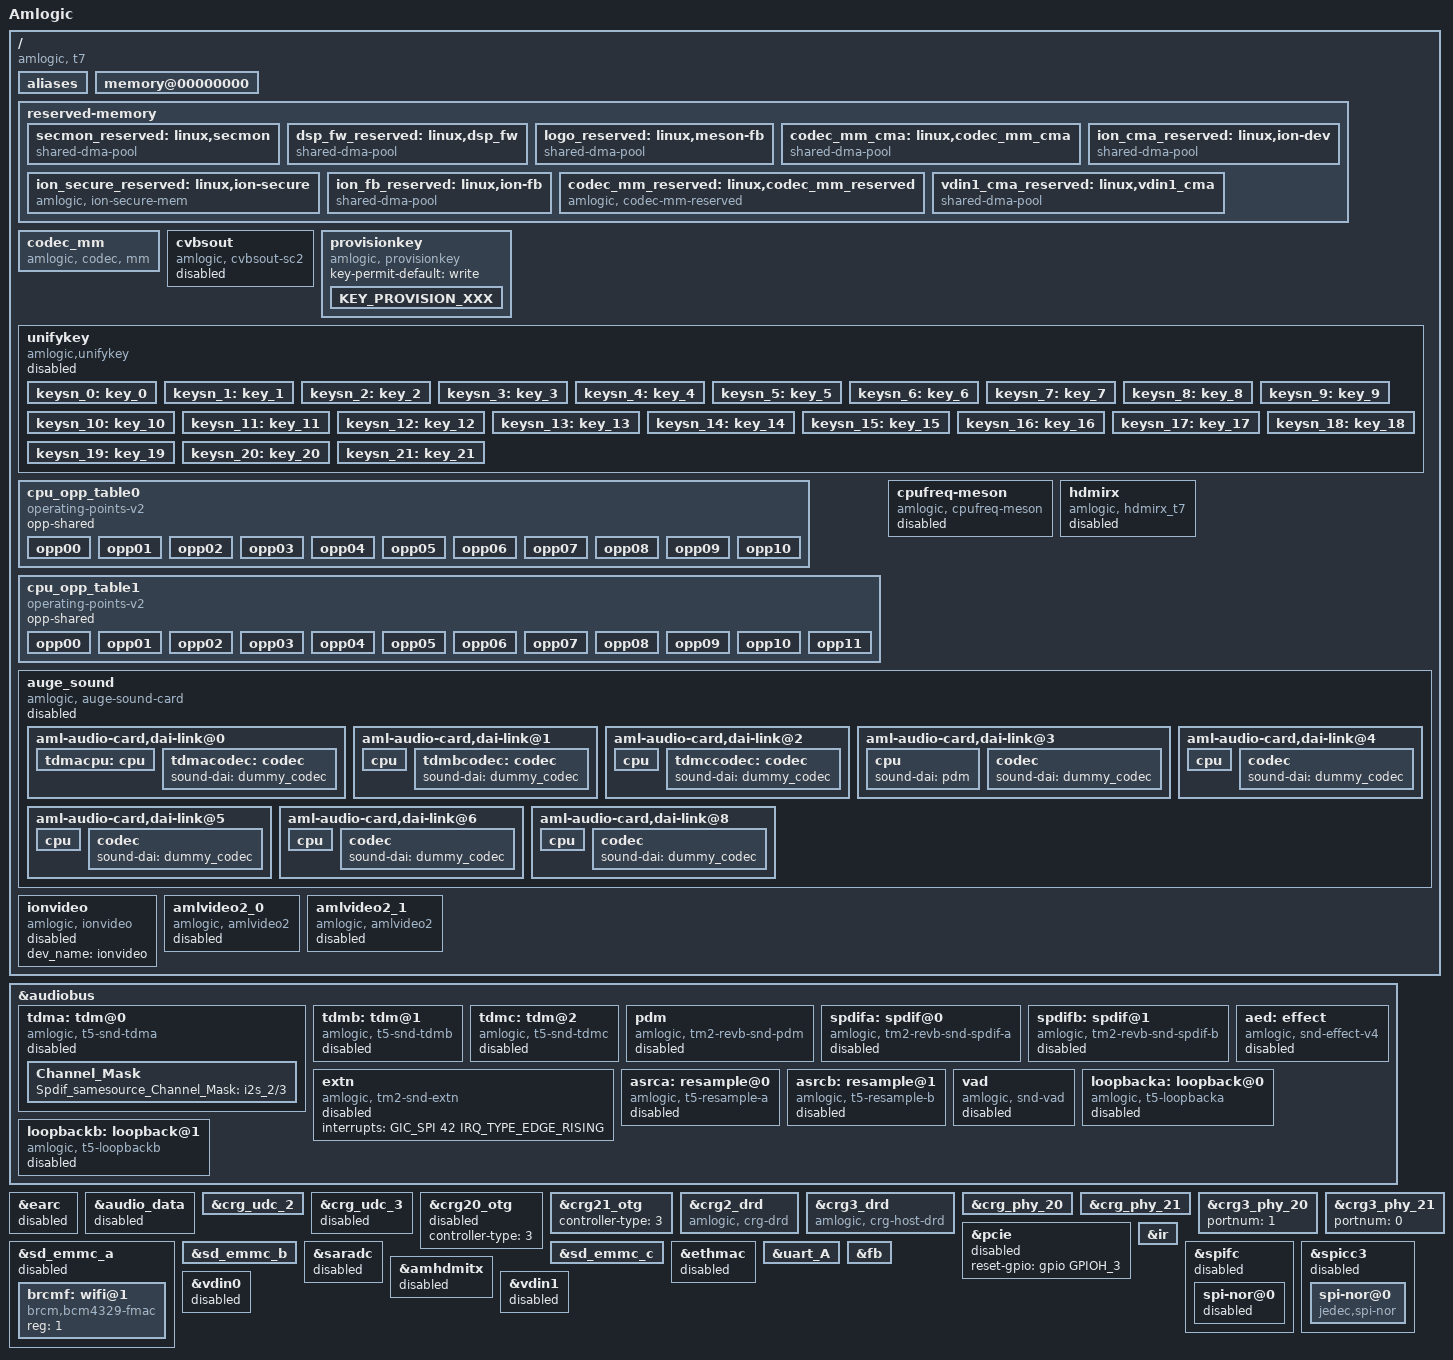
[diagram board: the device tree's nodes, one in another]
// SPDX-License-Identifier: (GPL-2.0+ OR MIT)
/*
 * Copyright (c) 2019 Amlogic, Inc. All rights reserved.
 */

/dts-v1/;

#include "mesont7.dtsi"
#include "partition_mbox_normal_P_32.dtsi"
#include <dt-bindings/input/input.h>
#include "mesont7_pxp-panel.dtsi"

/ {
	model = "Amlogic";
	amlogic-dt-id = "t7_pxp";
	compatible = "amlogic, t7";
	interrupt-parent = <&gic>;
	#address-cells = <2>;
	#size-cells = <2>;

	aliases {
		serial0 = &uart_A;
		serial1 = &uart_E;
		serial2 = &uart_C;
		serial3 = &uart_D;
		//serial4 = &uart_A;
		i2c0 = &i2c0;
		i2c1 = &i2c1;
		i2c2 = &i2c2;
		i2c3 = &i2c3;
		i2c4 = &i2c4;
		i2c5 = &i2c5;
		i2c6 = &i2c_AO_A;
		i2c7 = &i2c_AO_B;
		spi0 = &spifc;
		spi1 = &spicc0;
		spi2 = &spicc1;
		spi3 = &spicc2;
		spi4 = &spicc3;
		spi5 = &spicc4;
		spi6 = &spicc5;
		tsensor0 = &a73_tsensor;
		tsensor1 = &a53_tsensor;
		tsensor2 = &gpu_tsensor;
		tsensor3 = &nna_tsensor;
		tsensor4 = &hevc_tsensor;
		tsensor5 = &vpu_tsensor;
	};

	memory@00000000 {
		device_type = "memory";
		linux,usable-memory = <0x0 0x000000 0x0 0x40000000>;
	};

	reserved-memory {
		#address-cells = <2>;
		#size-cells = <2>;
		ranges;

		secmon_reserved:linux,secmon {
			compatible = "shared-dma-pool";
			reusable;
			size = <0x0 0x3400000>;
			alignment = <0x0 0x400000>;
			alloc-ranges = <0x0 0x05000000 0x0 0x3400000>;
			clear-map;
		};

		dsp_fw_reserved:linux,dsp_fw {
			compatible = "shared-dma-pool";
			reusable;
			size = <0x0 0x1000000>;
			alignment = <0x0 0x400000>;
			alloc-ranges = <0x0 0x40000000 0x0 0x1000000>;
		};

		/*dsp_shm_reserved:linux,dsp_shm {      */
		/*	compatible = "dspshmem";            */
		/*	reg = <0x0 0x40820000 0x0 0x80000>; */
		/*	size = <0x80000>;                   */
		/*};*/

		logo_reserved:linux,meson-fb {
			compatible = "shared-dma-pool";
			reusable;
			size = <0x0 0x800000>;
			alignment = <0x0 0x400000>;
			alloc-ranges = <0x0 0x3f800000 0x0 0x800000>;
		};

		codec_mm_cma:linux,codec_mm_cma {
			compatible = "shared-dma-pool";
			reusable;
			/* ion_codec_mm max can alloc size 80M*/
			size = <0x0 0xd000000>;
			alignment = <0x0 0x400000>;
			linux,contiguous-region;
			clear-map;
		};

		ion_cma_reserved:linux,ion-dev {
			compatible = "shared-dma-pool";
			reusable;
			size = <0x0 0x9800000>;
			alignment = <0x0 0x400000>;
		};
		/* secure ion for gpu,advice size is 0x8000000 */
		ion_secure_reserved:linux,ion-secure {
			compatible = "amlogic, ion-secure-mem";
			no-map;
			size = <0x0 0x0>;
			alignment = <0x0 0x400000>;
		};
		ion_fb_reserved:linux,ion-fb {
			compatible = "shared-dma-pool";
			reusable;
			/* 1920x1080x4x3 round up 4M align */
			size = <0x0 0x1c00000>;
			alignment = <0x0 0x400000>;
		};
		/* codec shared reserved */
		codec_mm_reserved:linux,codec_mm_reserved {
			compatible = "amlogic, codec-mm-reserved";
			size = <0x0 0x0>;
			alignment = <0x0 0x100000>;
			//no-map;
		};

		/*  vdin0 CMA pool */
		/*vdin0_cma_reserved:linux,vdin0_cma {*/
		/*	compatible = "shared-dma-pool";*/
		/*	reusable;*/
			/* up to 1920x1080 yuv422 8bit and 5 buffers
			 * 1920x1080x2x5 = 20 M
			 */
		/*	size = <0x0 0x01400000>;*/
		/*	alignment = <0x0 0x400000>;*/
		/*};*/
		/*  vdin1 CMA pool */
		vdin1_cma_reserved:linux,vdin1_cma {
			compatible = "shared-dma-pool";
			reusable;
			/* up to 1920x1080 yuv422 8bit and 5 buffers
			 * 1920x1080x2x5 = 20 M
			 */
			size = <0x0 0x01400000>;
			alignment = <0x0 0x400000>;
		};
	};
	codec_mm {
		compatible = "amlogic, codec, mm";
		memory-region = <&codec_mm_cma &codec_mm_reserved>;
		dev_name = "codec_mm";
		status = "okay";
	};

	cvbsout {
		compatible = "amlogic, cvbsout-sc2";
		status = "disabled";

		/* clk path */
		/* 0:vid_pll vid2_clk */
		/* 1:gp0_pll vid2_clk */
		/* 2:vid_pll vid1_clk */
		/* 3:gp0_pll vid1_clk */
		clk_path = <0>;

		/* performance: reg_address, reg_value */
		/* tm2 */
		performance = <0x1bf0  0x9
			0x1b56  0x333
			0x1b12  0x8080
			0x1b05  0xfd
			0x1c59  0xf850
			0xffff  0x0>; /* ending flag */
		performance_sarft = <0x1bf0  0x9
			0x1b56  0x333
			0x1b12  0x0
			0x1b05  0x9
			0x1c59  0xfc48
			0xffff  0x0>; /* ending flag */
		performance_revB_telecom = <0x1bf0  0x9
			0x1b56  0x546
			0x1b12  0x8080
			0x1b05  0x9
			0x1c59  0xf850
			0xffff  0x0>; /* ending flag */
	};

	provisionkey {
		compatible = "amlogic, provisionkey";
		status = "okay";
		key-permit-default = "write";
		//new key not need add dts if started with KEY_PROVISION_
		KEY_PROVISION_XXX { };
		//test_my_added_keyname { };
	};//End provisionkey

	unifykey{
		compatible = "amlogic,unifykey";
		status = "disabled";
		unifykey-num = <19>;
		unifykey-index-0 = <&keysn_0>;
		unifykey-index-1 = <&keysn_1>;
		unifykey-index-2 = <&keysn_2>;
		unifykey-index-3 = <&keysn_3>;
		unifykey-index-4 = <&keysn_4>;
		unifykey-index-5 = <&keysn_5>;
		unifykey-index-6 = <&keysn_6>;
		unifykey-index-7 = <&keysn_7>;
		unifykey-index-8 = <&keysn_8>;
		unifykey-index-9 = <&keysn_9>;
		unifykey-index-10= <&keysn_10>;
		unifykey-index-11= <&keysn_11>;
		unifykey-index-12= <&keysn_12>;
		unifykey-index-13= <&keysn_13>;
		unifykey-index-14= <&keysn_14>;
		unifykey-index-15= <&keysn_15>;
		unifykey-index-16= <&keysn_16>;
		unifykey-index-17= <&keysn_17>;
		unifykey-index-18= <&keysn_18>;
		unifykey-index-19= <&keysn_19>;
		unifykey-index-20= <&keysn_20>;
		unifykey-index-21= <&keysn_21>;

		keysn_0: key_0{
			key-name = "usid";
			key-device = "normal";
			key-permit = "read","write","del";
		};
		keysn_1:key_1{
			key-name = "mac";
			key-device = "normal";
			key-permit = "read","write","del";
		};
		keysn_2:key_2{
			key-name = "hdcp";
			key-device = "secure";
			key-type = "sha1";
			key-permit = "read","write","del";
		};
		keysn_3:key_3{
			key-name = "secure_boot_set";
			key-device = "efuse";
			key-permit = "write";
		};
		keysn_4:key_4{
			key-name = "mac_bt";
			key-device = "normal";
			key-permit = "read","write","del";
			key-type  = "mac";
		};
		keysn_5:key_5{
			key-name = "mac_wifi";
			key-device = "normal";
			key-permit = "read","write","del";
			key-type = "mac";
		};
		keysn_6:key_6{
			key-name = "hdcp2_tx";
			key-device = "normal";
			key-permit = "read","write","del";
		};
		keysn_7:key_7{
			key-name = "hdcp2_rx";
			key-device = "normal";
			key-permit = "read","write","del";
		};
		keysn_8:key_8{
			key-name = "widevinekeybox";
			key-device = "secure";
			key-permit = "read","write","del";
		};
		keysn_9:key_9{
			key-name = "deviceid";
			key-device = "normal";
			key-permit = "read","write","del";
		};
		keysn_10:key_10{
			key-name = "hdcp22_fw_private";
			key-device = "secure";
			key-permit = "read","write","del";
		};
		keysn_11:key_11{
			key-name = "PlayReadykeybox25";
			key-device = "secure";
			key-permit = "read","write","del";
		};
		keysn_12:key_12{
			key-name = "prpubkeybox";// PlayReady
			key-device = "secure";
			key-permit = "read","write","del";
		};
		keysn_13:key_13{
			key-name = "prprivkeybox";// PlayReady
			key-device = "secure";
			key-permit = "read","write","del";
		};
		keysn_14:key_14{
			key-name = "attestationkeybox";// attestation key
			key-device = "secure";
			key-permit = "read","write","del";
		};
		keysn_15:key_15{
			key-name = "region_code";
			key-device = "normal";
			key-permit = "read","write","del";
		};
		keysn_16:key_16{
			key-name = "netflix_mgkid";
			key-device = "secure";
			key-permit = "read","write","del";
		};
		keysn_17:key_17{
			key-name = "attestationdevidbox";// attest dev id box
			key-device = "secure";
			key-permit = "read","write","del";
		};
		keysn_18:key_18{
			key-name = "oemkey";
			key-device = "normal";
			key-permit = "read","write","del";
		};
		keysn_19:key_19{
			key-name = "lcd";
			key-device = "normal";
			key-permit = "read","write","del";
		};
		keysn_20:key_20{
			key-name = "lcd_extern";
			key-device = "normal";
			key-permit = "read","write","del";
		};
		keysn_21:key_21{
			key-name = "backlight";
			key-device = "normal";
			key-permit = "read","write","del";
		};
	};//End unifykey

	cpu_opp_table0: cpu_opp_table0 {
		compatible = "operating-points-v2";
		opp-shared;

		opp00 {
			opp-hz = /bits/ 64 <500000000>;
			opp-microvolt = <740000>;
		};
		opp01 {
			opp-hz = /bits/ 64 <666000000>;
			opp-microvolt = <740000>;
		};
		opp02 {
			opp-hz = /bits/ 64 <1000000000>;
			opp-microvolt = <770000>;
		};
		opp03 {
			opp-hz = /bits/ 64 <1200000000>;
			opp-microvolt = <790000>;
		};
		opp04 {
			opp-hz = /bits/ 64 <1392000000>;
			opp-microvolt = <820000>;
		};
		opp05 {
			opp-hz = /bits/ 64 <1512000000>;
			opp-microvolt = <870000>;
		};
		opp06 {
			opp-hz = /bits/ 64 <1608000000>;
			opp-microvolt = <910000>;
		};
		opp07 {
			opp-hz = /bits/ 64 <1704000000>;
			opp-microvolt = <960000>;
		};
		opp08 {
			opp-hz = /bits/ 64 <1800000000>;
			opp-microvolt = <980000>;
		};
		opp09 {
			opp-hz = /bits/ 64 <1896000000>;
			opp-microvolt = <1000000>;
		};
		opp10 {
			opp-hz = /bits/ 64 <2016000000>;
			opp-microvolt = <1030000>;
		};
	};

	cpu_opp_table1: cpu_opp_table1 {
		compatible = "operating-points-v2";
		opp-shared;

		opp00 {
			opp-hz = /bits/ 64 <500000000>;
			opp-microvolt = <739000>;
		};
		opp01 {
			opp-hz = /bits/ 64 <666000000>;
			opp-microvolt = <739000>;
		};
		opp02 {
			opp-hz = /bits/ 64 <1000000000>;
			opp-microvolt = <769000>;
		};
		opp03 {
			opp-hz = /bits/ 64 <1200000000>;
			opp-microvolt = <799000>;
		};
		opp04 {
			opp-hz = /bits/ 64 <1392000000>;
			opp-microvolt = <829000>;
		};
		opp05 {
			opp-hz = /bits/ 64 <1512000000>;
			opp-microvolt = <869000>;
		};
		opp06 {
			opp-hz = /bits/ 64 <1608000000>;
			opp-microvolt = <899000>;
		};
		opp07 {
			opp-hz = /bits/ 64 <1704000000>;
			opp-microvolt = <919000>;
		};
		opp08 {
			opp-hz = /bits/ 64 <1800000000>;
			opp-microvolt = <939000>;
		};
		opp09 {
			opp-hz = /bits/ 64 <1896000000>;
			opp-microvolt = <969000>;
		};
		opp10 {
			opp-hz = /bits/ 64 <2016000000>;
			opp-microvolt = <999000>;
		};
		opp11 {
			opp-hz = /bits/ 64 <2208000000>;
			opp-microvolt = <1029000>;
		};
	};

	cpufreq-meson {
		compatible = "amlogic, cpufreq-meson";
		status = "disabled";
	};

	hdmirx {
		compatible = "amlogic, hdmirx_t7";
		#address-cells=<1>;
		#size-cells=<1>;
		/*memory-region = <&hdmirx_emp_cma_reserved>;*/
		status = "disabled";
		pinctrl-names = "hdmirx_pins";
		pinctrl-0 = <&hdmirx_a_mux &hdmirx_b_mux
			&hdmirx_c_mux>;
		repeat = <0>;
		interrupts = <0 57 IRQ_TYPE_LEVEL_HIGH>;
		clocks =<&clkc CLKID_HDMIRX_CFG>,
			   <&clkc CLKID_HDMIRX_ACR>,
			   <&clkc CLKID_HDMIRX_METER>,
			   <&clkc CLKID_HDMIRX_2M>,
			   <&clkc CLKID_HDMIRX_5M>,
			   <&clkc CLKID_HDMIRX_HDCP>,
			   <&xtal>,
			   <&clkc CLKID_FCLK_DIV4>,
			   <&clkc CLKID_FCLK_DIV5>;
		clock-names = "cts_hdmirx_cfg_clk",
				"cts_hdmirx_acr_ref_clk",
				"cts_hdmirx_meter_clk",
				"cts_hdmirx_2m_clk",
				"cts_hdmirx_5m_clk",
				"cts_hdmirx_hdcp2x_eclk",
				"xtal",
				"fclk_div4",
				"fclk_div5";
		hdmirx_id = <0>;
		en_4k_2_2k = <0>;
		hpd_low_cec_off = <1>;
		arc_port = <1>;
		/* bit4: enable feature, bit3~0: port number */
		disable_port = <0x0>;
		/* MAP_ADDR_MODULE_CBUS */
		/* MAP_ADDR_MODULE_HIU */
		/* MAP_ADDR_MODULE_HDMIRX_CAPB3 */
		/* MAP_ADDR_MODULE_SEC_AHB */
		/* MAP_ADDR_MODULE_SEC_AHB2 */
		/* MAP_ADDR_MODULE_APB4 */
		/* MAP_ADDR_MODULE_TOP */
		/* MAP_ADDR_MODULE_CLK_CTRL */
		reg = < 0x0 0x0 0x0 0x0
			0x0 0xff63C000 0x0 0x2000
			0x0 0xffe0d000 0x0 0x2000
			0x0 0x0 0x0 0x0
			0x0 0x0 0x0 0x0
			0x0 0x0 0x0 0x0
			0x0 0xfe398000 0x0 0x7fff
			0x0 0xfe000000 0x0 0x1fff>;
	};

	/* Audio Related start */
	auge_sound {
		compatible = "amlogic, auge-sound-card";
		aml-audio-card,name = "AML-AUGESOUND";

		/*avout mute gpio*/
		//avout_mute-gpios = <&gpio GPIOH_5 GPIO_ACTIVE_HIGH>;
		//spk_mute-gpios = <&gpio GPIOD_2 GPIO_ACTIVE_LOW>;

		interrupts = <GIC_SPI 51 IRQ_TYPE_EDGE_RISING>;
		interrupt-names = "audio_exception64";

		status = "disabled";

		aml-audio-card,dai-link@0 {
			format = "i2s";
			mclk-fs = <256>;
			continuous-clock;
			//bitclock-inversion;
			//frame-inversion;
			/* master mode */
			bitclock-master = <&tdma>;
			frame-master = <&tdma>;
			/* slave mode */
			/*
			 * bitclock-master = <&tdmacodec>;
			 * frame-master = <&tdmacodec>;
			 */
			/* suffix-name, sync with android audio hal used for */
			suffix-name = "alsaPORT-i2s";
			tdmacpu: cpu {
				sound-dai = <&tdma>;
				dai-tdm-slot-tx-mask =
							<1 1>;
				dai-tdm-slot-rx-mask =
							<1 1>;
				dai-tdm-slot-num = <2>;
				dai-tdm-slot-width = <32>;
				system-clock-frequency = <12288000>;
			};
			tdmacodec: codec {
				sound-dai = <&dummy_codec>;
				//prefix-names = "AMP", "AMP1";
				//sound-dai = <&ad82584f &ad82584f1 &tl1_codec>;
			};
		};

		aml-audio-card,dai-link@1 {
			format = "i2s";
			mclk-fs = <256>;
			//continuous-clock;
			//bitclock-inversion;
			//frame-inversion;
			/* master mode */
			bitclock-master = <&tdmb>;
			frame-master = <&tdmb>;
			/* slave mode */
			//bitclock-master = <&tdmbcodec>;
			//frame-master = <&tdmbcodec>;
			/* suffix-name, sync with android audio hal used for */
			suffix-name = "alsaPORT-pcm";
			cpu {
				sound-dai = <&tdmb>;
				dai-tdm-slot-tx-mask = <1 1>;
				dai-tdm-slot-rx-mask = <1 1>;
				dai-tdm-slot-num = <2>;
				/*
				 * dai-tdm-slot-tx-mask =
				 *	<1 1 1 1 1 1 1 1>;
				 * dai-tdm-slot-rx-mask =
				 *	<1 1 1 1 1 1 1 1>;
				 * dai-tdm-slot-num = <8>;
				 */
				dai-tdm-slot-width = <32>;
				system-clock-frequency = <12288000>;
			};
			tdmbcodec: codec {
				sound-dai = <&dummy_codec>;
			};
		};

		aml-audio-card,dai-link@2 {
			format = "i2s";
			mclk-fs = <256>;
			//continuous-clock;
			//bitclock-inversion;
			//frame-inversion;
			/* master mode */
			bitclock-master = <&tdmc>;
			frame-master = <&tdmc>;
			/* slave mode */
			//bitclock-master = <&tdmccodec>;
			//frame-master = <&tdmccodec>;
			/* suffix-name, sync with android audio hal used for */
			//suffix-name = "alsaPORT-tdm";
			cpu {
				sound-dai = <&tdmc>;
				dai-tdm-slot-tx-mask = <1 1>;
				dai-tdm-slot-rx-mask = <1 1>;
				dai-tdm-slot-num = <2>;
				dai-tdm-slot-width = <32>;
				system-clock-frequency = <12288000>;
			};
			tdmccodec: codec {
				sound-dai = <&dummy_codec>;
			};
		};

		aml-audio-card,dai-link@3 {
			mclk-fs = <64>;
			/* suffix-name, sync with android audio hal used for */
			suffix-name = "alsaPORT-pdm";
			cpu {
				sound-dai = <&pdm>;
			};
			codec {
				sound-dai = <&dummy_codec>;
			};
		};

		aml-audio-card,dai-link@4 {
			mclk-fs = <128>;
			continuous-clock;
			/* suffix-name, sync with android audio hal used for */
			suffix-name = "alsaPORT-spdif";
			cpu {
				sound-dai = <&spdifa>;
				system-clock-frequency = <6144000>;
			};
			codec {
				sound-dai = <&dummy_codec>;
			};
		};

		aml-audio-card,dai-link@5 {
			mclk-fs = <128>;
			suffix-name = "alsaPORT-spdifb";
			cpu {
				sound-dai = <&spdifb>;
				system-clock-frequency = <6144000>;
			};
			codec {
				sound-dai = <&dummy_codec>;
			};
		};

		aml-audio-card,dai-link@6 {
			mclk-fs = <256>;
			suffix-name = "alsaPORT-tv";
			cpu {
				sound-dai = <&extn>;
				system-clock-frequency = <12288000>;
			};
			codec {
				sound-dai = <&dummy_codec>;
			};
		};
#if 0
		aml-audio-card,dai-link@7 {
			mclk-fs = <256>;
			suffix-name = "alsaPORT-earc";
			cpu {
				sound-dai = <&earc>;
				system-clock-frequency = <12288000>;
			};
			codec {
				sound-dai = <&dummy_codec>;
			};
		};
#endif
		aml-audio-card,dai-link@8 {
			mclk-fs = <256>;
			continuous-clock;
			suffix-name = "alsaPORT-loopback";
			cpu {
				sound-dai = <&loopbacka>;
				system-clock-frequency = <12288000>;
			};
			codec {
				sound-dai = <&dummy_codec>;
			};
		};
	};
	/* Audio Related end */

	ionvideo {
		compatible = "amlogic, ionvideo";
		dev_name = "ionvideo";
		status = "disabled";
	};

	amlvideo2_0 {
		compatible = "amlogic, amlvideo2";
		dev_name = "amlvideo2";
		status = "disabled";
		amlvideo2_id = <0>;
		cma_mode = <1>;
	};

	amlvideo2_1 {
		compatible = "amlogic, amlvideo2";
		dev_name = "amlvideo2";
		status = "disabled";
		amlvideo2_id = <1>;
		cma_mode = <1>;
	};
};

&audiobus {
	tdma:tdm@0 {
		compatible = "amlogic, t5-snd-tdma";
		#sound-dai-cells = <0>;

		dai-tdm-lane-slot-mask-in = <1 0>;
		dai-tdm-lane-slot-mask-out = <1 1 1 1>;
		dai-tdm-clk-sel = <0>;

		clocks = <&clkaudio CLKID_AUDIO_MCLK_A
				&clkaudio CLKID_AUDIO_MCLK_PAD0
				&clkc CLKID_MPLL0
				&clkc CLKID_MPLL1
				&clkaudio CLKID_AUDIO_SPDIFOUT_A>;
		clock-names = "mclk", "mclk_pad", "clk_srcpll",
			"samesource_srcpll", "samesource_clk";

		//pinctrl-names = "tdm_pins";
		//pinctrl-0 = <&tdm_a>;

		/*
		 * 0: tdmout_a;
		 * 1: tdmout_b;
		 * 2: tdmout_c;
		 * 3: spdifout;
		 * 4: spdifout_b;
		 */
		samesource_sel = <3>;

		/* In for ACODEC_ADC */
		tdmin-src-name = "acodec_adc";
		/*enable default mclk(12.288M), before extern codec start*/
		start_clk_enable = <1>;

		/*tdm clk tuning enable*/
		clk_tuning_enable = <1>;
		status = "disabled";

		/* !!!For --TV platform-- ONLY */
		Channel_Mask {
			/*i2s has 4 pins, 8channel, mux output*/
			Spdif_samesource_Channel_Mask = "i2s_2/3";
		};
	};

	tdmb:tdm@1 {
		compatible = "amlogic, t5-snd-tdmb";
		#sound-dai-cells = <0>;

		dai-tdm-lane-slot-mask-in = <1 0 0 0>;
		dai-tdm-lane-slot-mask-out = <0 1 0 0>;
		dai-tdm-clk-sel = <1>;

		clocks = <&clkaudio CLKID_AUDIO_MCLK_B
				&clkc CLKID_MPLL1>;
		clock-names = "mclk", "clk_srcpll";

		status = "disabled";
	};

	tdmc:tdm@2 {
		compatible = "amlogic, t5-snd-tdmc";
		#sound-dai-cells = <0>;

		dai-tdm-lane-slot-mask-in = <1 0 0 0>;
		dai-tdm-lane-slot-mask-out = <1 0 0 0>;
		dai-tdm-clk-sel = <2>;

		clocks = <&clkaudio CLKID_AUDIO_MCLK_C
				&clkc CLKID_MPLL2>;
		clock-names = "mclk", "clk_srcpll";
		status = "disabled";
	};

	pdm:pdm {
		compatible = "amlogic, tm2-revb-snd-pdm";
		#sound-dai-cells = <0>;

		clocks = <&clkaudio CLKID_AUDIO_GATE_PDM
			&clkc CLKID_FCLK_DIV3
			&clkc CLKID_MPLL3
			&clkaudio CLKID_AUDIO_PDMIN0
			&clkaudio CLKID_AUDIO_PDMIN1>;
		clock-names = "gate",
			"sysclk_srcpll",
			"dclk_srcpll",
			"pdm_dclk",
			"pdm_sysclk";

		//pinctrl-names = "pdm_pins";
		//pinctrl-0 = <&pdmin>;

		/* mode 0~4, defalut:1 */
		filter_mode = <1>;

		status = "disabled";
	};

	spdifa:spdif@0 {
		compatible = "amlogic, tm2-revb-snd-spdif-a";
		#sound-dai-cells = <0>;

		clocks = <&clkc CLKID_MPLL0
				&clkc CLKID_FCLK_DIV4
				&clkaudio CLKID_AUDIO_GATE_SPDIFIN
				&clkaudio CLKID_AUDIO_GATE_SPDIFOUT_A
				&clkaudio CLKID_AUDIO_SPDIFIN
				&clkaudio CLKID_AUDIO_SPDIFOUT_A>;
		clock-names = "sysclk", "fixed_clk", "gate_spdifin",
				"gate_spdifout", "clk_spdifin", "clk_spdifout";
		interrupts =
				<GIC_SPI 35 IRQ_TYPE_EDGE_RISING>;

		interrupt-names = "irq_spdifin";
		//pinctrl-names = "spdif_pins", "spdif_pins_mute";
		//pinctrl-0 = <&spdifout>;
		//pinctrl-1 = <&spdifout_a_mute>;

		samesource_sel = <4>;

		/*spdif clk tuning enable*/
		clk_tuning_enable = <1>;
		status = "disabled";
	};
	spdifb:spdif@1 {
		compatible = "amlogic, tm2-revb-snd-spdif-b";
		#sound-dai-cells = <0>;
		clocks = <&clkc CLKID_MPLL2 /*CLKID_HIFI_PLL*/
				&clkaudio CLKID_AUDIO_GATE_SPDIFOUT_B
				&clkaudio CLKID_AUDIO_SPDIFOUT_B>;
		clock-names = "sysclk",
				"gate_spdifout", "clk_spdifout";

		status = "disabled";
	};

	extn:extn {
		compatible = "amlogic, tm2-snd-extn";
		#sound-dai-cells = <0>;

		interrupts =
				<GIC_SPI 42 IRQ_TYPE_EDGE_RISING>;
		interrupt-names = "irq_frhdmirx";

		status = "disabled";
	};

	aed:effect {
		compatible = "amlogic, snd-effect-v4";
		#sound-dai-cells = <0>;

		clocks = <&clkaudio CLKID_AUDIO_GATE_EQDRC
			&clkc CLKID_FCLK_DIV5
			&clkaudio CLKID_AUDIO_EQDRC>;
		clock-names = "gate", "srcpll", "eqdrc";

		/*
		 * 0:tdmout_a
		 * 1:tdmout_b
		 * 2:tdmout_c
		 * 3:spdifout
		 * 4:spdifout_b
		 */
		eqdrc_module = <0>;
		/* max 0xf, each bit for one lane, usually one lane */
		lane_mask = <0x1>;
		/* max 0xff, each bit for one channel */
		channel_mask = <0xff>;

		status = "disabled";
	};

	asrca:resample@0 {
		compatible = "amlogic, t5-resample-a";
		clocks = <&clkc CLKID_MPLL1
			&clkaudio CLKID_AUDIO_MCLK_B
			&clkaudio CLKID_AUDIO_RESAMPLE_A>;
		clock-names = "resample_pll", "resample_src", "resample_clk";

		/*same with toddr_src
		 *	TDMIN_A,    0
		 *	TDMIN_B,    1
		 *	TDMIN_C,    2
		 *	SPDIFIN,    3
		 *	PDMIN,      4
		 *	FRATV,      5
		 *	TDMIN_LB,   6
		 *	LOOPBACK_A, 7
		 *	FRHDMIRX,   8
		 *	LOOPBACK_B, 9
		 *	SPDIFIN_LB, 10
		 *	EARC_RX,    11
		 */
		resample_module = <8>;

		status = "disabled";
	};

	asrcb:resample@1 {
		compatible = "amlogic, t5-resample-b";
		clocks = <&clkc CLKID_MPLL3
			&clkaudio CLKID_AUDIO_MCLK_F
			&clkaudio CLKID_AUDIO_RESAMPLE_B>;
		clock-names = "resample_pll", "resample_src", "resample_clk";

		/*this resample is only used for loopback_A.*/

		status = "disabled";
	};

	vad:vad {
		compatible = "amlogic, snd-vad";
		#sound-dai-cells = <0>;

		clocks = <&clkaudio CLKID_AUDIO_GATE_TOVAD
			&clkc CLKID_FCLK_DIV5
			&clkaudio CLKID_AUDIO_VAD>;
		clock-names = "gate", "pll", "clk";

		interrupts = <GIC_SPI 39 IRQ_TYPE_EDGE_RISING
				GIC_SPI 44 IRQ_TYPE_EDGE_RISING>;
		interrupt-names = "irq_wakeup", "irq_frame_sync";

		/*
		 * Data src sel:
		 * 0: tdmin_a;
		 * 1: tdmin_b;
		 * 2: tdmin_c;
		 * 3: spdifin;
		 * 4: pdmin;
		 * 5: loopback_b;
		 * 6: tdmin_lb;
		 * 7: loopback_a;
		 */
		src = <4>;

		/*
		 * deal with hot word in user space or kernel space
		 * 0: in user space
		 * 1: in kernel space
		 */
		level = <1>;

		status = "disabled";
	};

	loopbacka:loopback@0 {
		compatible = "amlogic, t5-loopbacka";
		#sound-dai-cells = <0>;

		clocks = <&clkaudio CLKID_AUDIO_GATE_PDM
			&clkc CLKID_FCLK_DIV3
			&clkc CLKID_MPLL3
			&clkaudio CLKID_AUDIO_PDMIN0
			&clkaudio CLKID_AUDIO_PDMIN1
			&clkc CLKID_MPLL0
			&clkaudio CLKID_AUDIO_MCLK_A>;
		clock-names = "pdm_gate",
			"pdm_sysclk_srcpll",
			"pdm_dclk_srcpll",
			"pdm_dclk",
			"pdm_sysclk",
			"tdminlb_mpll",
			"tdminlb_mclk";

		/* datain src
		 * 0: tdmin_a;
		 * 1: tdmin_b;
		 * 2: tdmin_c;
		 * 3: spdifin;
		 * 4: pdmin;
		 */
		datain_src = <4>;
		datain_chnum = <4>;
		datain_chmask = <0xf>;
		/* config which data pin for loopback */
		datain-lane-mask-in = <1 0 1 0>;

		/* calc mclk for datalb */
		mclk-fs = <256>;

		/* tdmin_lb src
		 * 0: tdmoutA
		 * 1: tdmoutB
		 * 2: tdmoutC
		 * 3: PAD_TDMINA_DIN*, refer to core pinmux
		 * 4: PAD_TDMINB_DIN*, refer to core pinmux
		 * 5: PAD_TDMINC_DIN*, refer to core pinmux
		 * 6: PAD_TDMINA_D*, oe, refer to core pinmux
		 * 7: PAD_TDMINB_D*, oe, refer to core pinmux
		 */
		/* if tdmin_lb >= 3, use external loopback */
		datalb_src = <0>;
		datalb_chnum = <2>;
		datalb_chmask = <0x3>;
		/* config which data pin as loopback */
		datalb-lane-mask-in = <1 0 0 0>;

		status = "disabled";
	};

	loopbackb:loopback@1 {
		compatible = "amlogic, t5-loopbackb";
		#sound-dai-cells = <0>;

		clocks = <&clkaudio CLKID_AUDIO_GATE_PDM
			&clkc CLKID_FCLK_DIV3
			&clkc CLKID_MPLL3
			&clkaudio CLKID_AUDIO_PDMIN0
			&clkaudio CLKID_AUDIO_PDMIN1
			&clkc CLKID_MPLL0
			&clkaudio CLKID_AUDIO_MCLK_A>;
		clock-names = "pdm_gate",
			"pdm_sysclk_srcpll",
			"pdm_dclk_srcpll",
			"pdm_dclk",
			"pdm_sysclk",
			"tdminlb_mpll",
			"tdminlb_mclk";

		/* calc mclk for datain_lb */
		mclk-fs = <256>;

		/* datain src
		 * 0: tdmin_a;
		 * 1: tdmin_b;
		 * 2: tdmin_c;
		 * 3: spdifin;
		 * 4: pdmin;
		 */
		datain_src = <4>;
		datain_chnum = <4>;
		datain_chmask = <0xf>;
		/* config which data pin for loopback */
		datain-lane-mask-in = <1 0 1 0>;

		/* tdmin_lb src
		 * 0: tdmoutA
		 * 1: tdmoutB
		 * 2: tdmoutC
		 * 3: PAD_TDMINA_DIN*, refer to core pinmux
		 * 4: PAD_TDMINB_DIN*, refer to core pinmux
		 * 5: PAD_TDMINC_DIN*, refer to core pinmux
		 * 6: PAD_TDMINA_D*, oe, refer to core pinmux
		 * 7: PAD_TDMINB_D*, oe, refer to core pinmux
		 */
		/* if tdmin_lb >= 3, use external loopback */
		datalb_src = <1>;
		datalb_chnum = <2>;
		datalb_chmask = <0x3>;
		/* config which data pin as loopback */
		datalb-lane-mask-in = <1 0 0 0>;

		status = "disabled";
	};
}; /* end of audiobus */

&earc {
	status = "disabled";
};

&audio_data {
	status = "disabled";
};

&crg_udc_2 {
	status = "okay";
};

&crg_udc_3 {
	status = "disable";
};

&crg20_otg {
	status = "disable";
	controller-type = <3>;
};

&crg21_otg {
	status = "okay";
	controller-type = <3>;
};

&crg2_drd {
	compatible = "amlogic, crg-drd";
	/*compatible = "amlogic, crg-host-drd";*/
	status = "okay";
};

&crg3_drd {
	compatible = "amlogic, crg-host-drd";
	/*compatible = "amlogic, crg-drd";*/
	status = "okay";
};

&crg_phy_20 {
	status = "okay";
	portnum = <1>;
	gpio-vbus-power = "GPIOM_8";
	gpios = <&gpio GPIOM_8 GPIO_ACTIVE_HIGH>;
};

&crg_phy_21 {
	status = "okay";
	portnum = <1>;
	gpio-vbus-power = "GPIOM_9";
	gpios = <&gpio GPIOM_9 GPIO_ACTIVE_HIGH>;
};

&crg3_phy_20 {
	status = "okay";
	portnum = <1>;
};

&crg3_phy_21 {
	status = "okay";
	portnum = <0>;
};

&pcie {
	reset-gpio = <&gpio GPIOH_3 GPIO_ACTIVE_HIGH>;
	status = "disable";
};

/* SDIO */
&sd_emmc_a {
	status = "disabled";
	pinctrl-0 = <&sdio_pins>;
	pinctrl-1 = <&sdio_clk_gate_pins>;
	pinctrl-names = "default", "clk-gate";
	#address-cells = <1>;
	#size-cells = <0>;

	bus-width = <4>;
	cap-sd-highspeed;
	sd-uhs-sdr50;
	sd_uhs-sdr104;
	max-frequency = <200000000>;

	non-removable;
	disable-wp;

	//vmmc-supply = <&vddao_3v3>;
	//vqmmc-supply = <&vddio_ao1v8>;

	brcmf: wifi@1 {
		reg = <1>;
		compatible = "brcm,bcm4329-fmac";
	};
};

/* SD card */
&sd_emmc_b {
	status = "okay";
	pinctrl-0 = <&sd_all_pins>;
	pinctrl-1 = <&sd_1bit_pins>;
	pinctrl-2 = <&sd_clk_gate_pins>;
	pinctrl-names = "sd_default",
			"sd_1bit_pins",
			"clk-gate";
	bus-width = <4>;
	cap-sd-highspeed;
//	sd-uhs-sdr12;
//	sd-uhs-sdr25;
//	sd-uhs-sdr50;
//	sd_uhs-sdr104;
	max-frequency = <200000000>;

	non-removable;
	disable-wp;

	cd-gpios = <&gpio GPIOC_6 GPIO_ACTIVE_HIGH>;
	//dat1-gpios = <&gpio GPIOC_1 GPIO_ACTIVE_HIGH>;
	//vmmc-supply = <&vddao_3v3>;
	//vqmmc-supply = <&emmc_1v8>;
};

&sd_emmc_c {
	status = "okay";
	pinctrl-0 = <&emmc_pins>, <&emmc_ds_pins>;
	pinctrl-1 = <&emmc_clk_gate_pins>;
	pinctrl-names = "default", "clk-gate";

	bus-width = <8>;
	cap-mmc-highspeed;
	//mmc-ddr-1_8v;
	//mmc-hs200-1_8v;
	//mmc-hs400-1_8v;
	max-frequency = <200000000>;
	non-removable;
	disable-wp;

//	mmc-pwrseq = <&emmc_pwrseq>;
//	vmmc-supply = <&vddao_3v3>;
//	vqmmc-supply = <&vddao_1v8>;
};

&saradc {
	status = "disabled";
};

&ethmac {
	status = "disabled";
	phy-handle = <&internal_ephy>;
	phy-mode = "rmii";
};

&uart_A {
	status = "okay";
};

&ir {
	status = "okay";
//	pinctrl-0 = <&remote_pins>;
//	pinctrl-names = "default";
};

&spifc {
	status = "disabled";
	spi-nor@0 {
		status = "disabled";
	};
};

&spicc3 {
	status = "disabled";
	pinctrl-names = "default";
	pinctrl-0 = <&spicc3_pins>;
	cs-gpios = <&gpio GPIOT_9 0>;
	spi-nor@0 {
		compatible = "jedec,spi-nor";
		status = "okay";
		reg = <0>;
		spi-max-frequency = <16000000>;
	};
};

&fb {
	status = "okay";
	display_size_default = <1920 1080 1920 2160 32>;
	mem_size = <0x00800000 0x1980000 0x100000 0x100000 0x100000>;
	logo_addr = "0x3f800000";
	mem_alloc = <0>;
	pxp_mode = <1>; /** 0:normal mode 1:pxp mode */
};

&amhdmitx {
	status = "disabled";
};

/*if you want to use vdin just modify status to "ok"*/
&vdin0 {
	/*memory-region = <&vdin0_cma_reserved>;*/
	status = "disabled";
	/*MByte, if 10bit disable: 64M(YUV422),
	 *if 10bit enable: 64*1.5 = 96M(YUV422)
	 *if support 4K2K-YUV444-10bit-WR:3840*2160*4*4 ~= 128M
	 *if support 4K2K-YUV422-10bit-wr:3840*2160*3*4 ~= 96M
	 *if support 4K2K-YUV422-8BIT-WR:3840*2160*2*4 ~= 64M
	 *if support 1080p-YUV422-8BIT-WR:1920*1080*2*4 ~= 16M
	 * onebuffer:
	 * worst case:(4096*2160*3 + 2M(afbce issue)) = 27.5M
	 * dw:960x540x3 = 1.5M
	 * total size:(27.5+1.5)x buffernumber
	 */
	cma_size = <174>;
	frame_buff_num = <6>;
	/*vdin write mem color depth support:
	 *bit0:support 8bit
	 *bit1:support 9bit
	 *bit2:support 10bit
	 *bit3:support 12bit
	 *bit4:support yuv422 10bit full pack mode (from txl new add)
	 */
	tv_bit_mode = <0x1>;
};

&vdin1 {
	memory-region = <&vdin1_cma_reserved>;
	status = "disabled";
	/*vdin write mem color depth support:
	 *bit0:support 8bit
	 *bit1:support 9bit
	 *bit2:support 10bit
	 *bit3:support 12bit
	 */
	tv_bit_mode = <1>;
};

